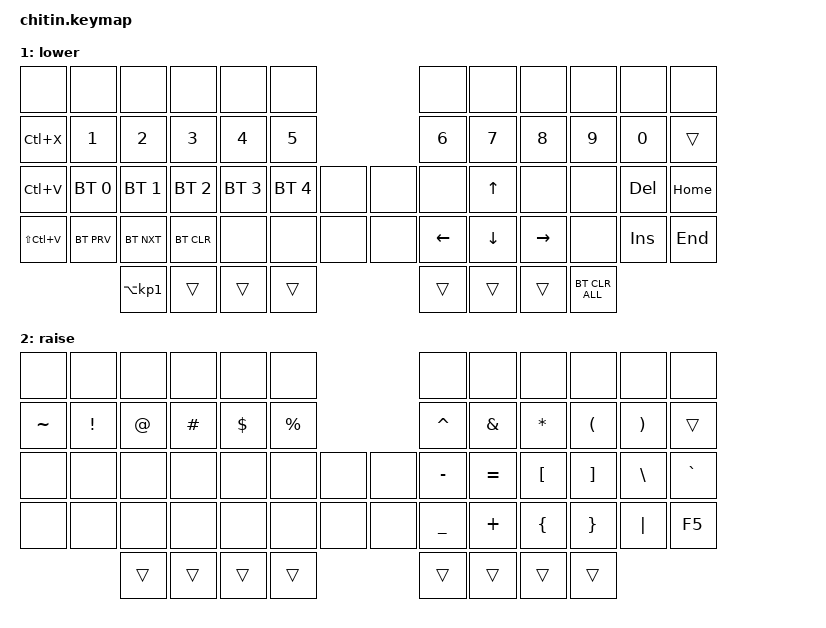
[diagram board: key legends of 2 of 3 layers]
#include <behaviors.dtsi>
#include <dt-bindings/zmk/bt.h>
#include <dt-bindings/zmk/keys.h>
#include <dt-bindings/zmk/pointing.h>
#include <dt-bindings/zmk/outputs.h>

/ {
    macros {
        paste_macro: paste_macro {
            compatible = "zmk,behavior-macro";
            #binding-cells = <0>;
            bindings = <&macro_press>, <&kp LS(LC(V))>, <&macro_release>;

            label = "PASTE_MACRO";
        };
    };

    behaviors {
        caps_behavior: caps_behavior {
            compatible = "zmk,behavior-tap-dance";
            label = "CAPS_BEHAVIOR";
            #binding-cells = <0>;
            bindings = <&kp LEFT_SHIFT>, <&kp CAPS>;
        };
    };

    keymap {
        compatible = "zmk,keymap";

        base {
            bindings = <
&none           &kp 1  &kp 2  &kp 3     &kp 4  &kp 5                     &kp 6      &kp 7       &kp 8      &kp 9       &kp 0     &none
&kp TAB         &kp Q  &kp W  &kp E     &kp R  &kp T                     &kp Y      &kp U       &kp I      &kp O       &kp P     &kp BACKSPACE
&kp LCTRL       &kp A  &kp S  &kp D     &kp F  &kp G      &none  &none   &kp H      &kp J       &kp K      &kp L       &kp SEMI  &kp SQT
&caps_behavior  &kp Z  &kp X  &kp C     &kp V  &kp B      &none  &none   &kp N      &kp M       &kp COMMA  &kp PERIOD  &kp FSLH  &kp ESC
                              &kp LGUI  &mo 1  &kp SPACE                 &kp ENTER  &kp RSHIFT  &mo 2      &kp RALT 
            >;
        };

        lower {
            bindings = <
&none          &none         &none                &none         &none         &none                            &none     &none     &none      &none           &none    &none
&kp LC(X)      &kp N1        &kp N2               &kp N3        &kp N4        &kp N5                           &kp N6    &kp N7    &kp N8     &kp N9          &kp N0   &trans
&kp LC(V)      &bt BT_SEL 0  &bt BT_SEL 1         &bt BT_SEL 2  &bt BT_SEL 3  &bt BT_SEL 4  &none  &none       &none     &kp UP    &none      &none           &kp DEL  &kp HOME
&kp LS(LC(V))  &bt BT_PRV    &bt BT_NXT           &bt BT_CLR    &none         &none         &none  &none       &kp LEFT  &kp DOWN  &kp RIGHT  &none           &kp INS  &kp END
                             &kp LA(KP_NUMBER_1)  &trans        &trans        &trans                           &trans    &trans    &trans     &bt BT_CLR_ALL
            >;
        };

        raise {
            bindings = <
&none          &none         &none                &none         &none         &none                            &none     &none     &none      &none           &none    &none
&kp TILDE  &kp EXCL  &kp AT  &kp HASH  &kp DLLR  &kp PRCNT        &kp CARET  &kp AMPS   &kp STAR  &kp LPAR  &kp RPAR  &trans
&none      &none     &none   &none     &none     &none   &none  &none          &kp MINUS  &kp EQUAL  &kp LBKT  &kp RBKT  &kp BSLH  &kp GRAVE
&none      &none     &none   &none     &none     &none    &none  &none         &kp UNDER  &kp PLUS   &kp LBRC  &kp RBRC  &kp PIPE  &kp F5
                     &trans  &trans    &trans    &trans           &trans     &trans     &trans    &trans
            >;
        };
    };
};
